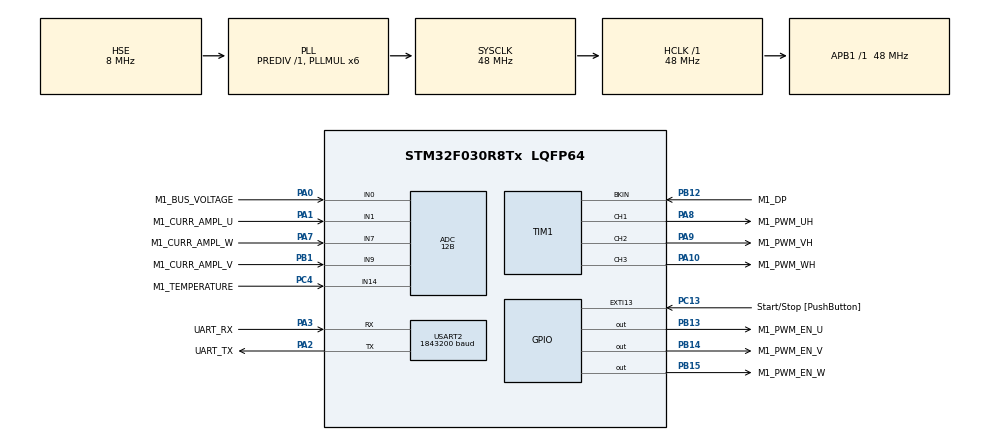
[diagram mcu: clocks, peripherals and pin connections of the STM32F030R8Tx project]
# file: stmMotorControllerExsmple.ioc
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ADC.ClockPrescaler=ADC_CLOCK_ASYNC_DIV1
ADC.ContinuousConvMode=DISABLE
ADC.DMAContinuousRequests=ENABLE
ADC.DataAlign=ADC_DATAALIGN_LEFT
ADC.DiscontinuousConvMode=DISABLE
ADC.EOCSelection=ADC_EOC_SINGLE_CONV
ADC.EnableAnalogWatchDog=false
ADC.ExternalTrigConv=ADC_EXTERNALTRIGCONV_T1_TRGO
ADC.ExternalTrigConvEdge=ADC_EXTERNALTRIGCONVEDGE_RISING
ADC.LowPowerAutoPowerOff=DISABLE
ADC.LowPowerAutoWait=DISABLE
ADC.Overrun=ADC_OVR_DATA_PRESERVED
ADC.Resolution=ADC_RESOLUTION_12B
ADC.SamplingTime=ADC_SAMPLETIME_7CYCLES_5
ADC.ScanConvMode=ADC_SCAN_DIRECTION_FORWARD
Dma.ADC.0.Direction=DMA_PERIPH_TO_MEMORY
Dma.ADC.0.Instance=DMA1_Channel1
Dma.ADC.0.MemDataAlignment=DMA_MDATAALIGN_HALFWORD
Dma.ADC.0.MemInc=DMA_MINC_ENABLE
Dma.ADC.0.Mode=DMA_CIRCULAR
Dma.ADC.0.PeriphDataAlignment=DMA_PDATAALIGN_HALFWORD
Dma.ADC.0.PeriphInc=DMA_PINC_DISABLE
Dma.ADC.0.Priority=DMA_PRIORITY_HIGH
Dma.Request0=ADC
Dma.Request1=USART2_RX
Dma.Request2=USART2_TX
Dma.USART2_RX.1.Direction=DMA_PERIPH_TO_MEMORY
Dma.USART2_RX.1.Instance=DMA1_Channel5
Dma.USART2_RX.1.MemDataAlignment=DMA_MDATAALIGN_BYTE
Dma.USART2_RX.1.MemInc=DMA_MINC_ENABLE
Dma.USART2_RX.1.Mode=DMA_NORMAL
Dma.USART2_RX.1.PeriphDataAlignment=DMA_PDATAALIGN_BYTE
Dma.USART2_RX.1.PeriphInc=DMA_PINC_DISABLE
Dma.USART2_RX.1.Priority=DMA_PRIORITY_LOW
Dma.USART2_TX.2.Direction=DMA_MEMORY_TO_PERIPH
Dma.USART2_TX.2.Instance=DMA1_Channel4
Dma.USART2_TX.2.MemDataAlignment=DMA_MDATAALIGN_BYTE
Dma.USART2_TX.2.MemInc=DMA_MINC_ENABLE
Dma.USART2_TX.2.Mode=DMA_NORMAL
Dma.USART2_TX.2.PeriphDataAlignment=DMA_PDATAALIGN_BYTE
Dma.USART2_TX.2.PeriphInc=DMA_PINC_DISABLE
Dma.USART2_TX.2.Priority=DMA_PRIORITY_LOW
ExtraMW=MotorControl
ExtraMW.MotorControl.Config=MotorControl
ExtraMW.MotorControl.Mode=MotorControl
ExtraMW.MotorControl.Root=MCSDK_v6.3.0-Full/MotorControl
ExtraMW.MotorControl.Template=templates
Mcu.Family=STM32F0
Mcu.Name=STM32F030R8Tx
Mcu.Package=LQFP64
MotorControl.ADC_AHBPERIPH=RCC_AHBPeriph_ADC
MotorControl.ADC_CLOCK_WB_DIV=1
MotorControl.ADC_PERIPH=ADC1
MotorControl.ADC_REFERENCE_VOLTAGE=3.3
MotorControl.BOARD=NUCLEO-F030R8
MotorControl.BUS_VOLTAGE_READING=true
MotorControl.CCMRAM_ENABLED=false
MotorControl.CLOCK_FREQUENCY=CPU_CLK_48_MHZ
MotorControl.CLOCK_SOURCE=EXTERNAL
MotorControl.CPU_CLK_48_MHZ=true
MotorControl.CTLBOARD_NAME=NUCLEO-F030R8
MotorControl.CUBE_MX_VER=6.11.1
MotorControl.CURRENT_READING_TOPOLOGY=THREE_SHUNT
MotorControl.CURR_SAMPLING_TIME=7
MotorControl.DBG_MCU_LOAD_MEASURE=false
MotorControl.DEBUG_DAC_FUNCTIONALITY_EN=false
MotorControl.DP_EMERGENCY_STOP_GPIO_PIN=LL_GPIO_PIN_12
MotorControl.DP_EMERGENCY_STOP_GPIO_PORT=GPIOB
MotorControl.DRIVES_NUMBER_SELECTION=SINGLEDRIVE
MotorControl.DRIVE_NUMBER=1
MotorControl.DRIVE_TYPE=FOC
MotorControl.ENCODER_AVAILABLE=false
MotorControl.ENCODER_PPR=400
MotorControl.EXT_CLK_8_MHZ=true
MotorControl.EXT_CLOCK_FREQUENCY=EXT_CLK_8_MHZ
MotorControl.FEEDBACK_NET_FILTERING=false
MotorControl.HALL_SENSORS_AVAILABLE=false
MotorControl.HIGH_SIDE_IDLE_STATE=false
MotorControl.HWV_CS=ThreeShunt_AmplifiedCurrents
MotorControl.HWV_DP=SingleErrorTrigger_FixedReference
MotorControl.HWV_PWM=DrivingHighSidesAndThreeEnables
MotorControl.HW_COMPLEMENTED_LOW_SIDE=true
MotorControl.HW_DEAD_TIME_NS=550
MotorControl.IPs=NVIC,RCC,SYS,MotorControl,TIM1,ADC,USART2,DMA
MotorControl.LOW_MEMORY_FOOTPRINT_REG=false
MotorControl.LOW_SIDE_IDLE_STATE=false
MotorControl.LOW_SIDE_SIGNALS_ENABLING=ES_GPIO
MotorControl.M1_AMPLIFICATION_GAIN=1.53
MotorControl.M1_ANGC={0,0,0,0,0,0,0,0}
MotorControl.M1_AUXILIARY_SPEED_SENSOR=NONE
MotorControl.M1_BEMF_CONSISTENCY_GAIN=64
MotorControl.M1_BEMF_CONSISTENCY_TOL=64
MotorControl.M1_BOARD_MAX_CURRENT=1.2
MotorControl.M1_BUS_VOLTAGE_READING=true
MotorControl.M1_COMMUTATION_STEP_TIME_BUF_SIZE=12
MotorControl.M1_CONSTANT1_D=3445
MotorControl.M1_CONSTANT1_Q=3445
MotorControl.M1_CONSTANT2_QD=3257
MotorControl.M1_CS_ADC_NUM=1
MotorControl.M1_CS_ADC_PHASE_SHARED=NONE
MotorControl.M1_CS_ADC_U=ADC1
MotorControl.M1_CS_ADC_V=ADC1
MotorControl.M1_CS_ADC_W=ADC1
MotorControl.M1_CS_CHANNEL_U=1
MotorControl.M1_CS_CHANNEL_V=9
MotorControl.M1_CS_CHANNEL_W=7
MotorControl.M1_CURRENT_AMPLIFICATION_TOPO=EXTERNAL
MotorControl.M1_CURRENT_SENSING_TOPO=THREE_SHUNT
MotorControl.M1_CURR_SAMPLING_TIME=7
MotorControl.M1_DBG_OPEN_LOOP_ENABLE=false
MotorControl.M1_DC_CURRENT_RS_MEAS=1.2
MotorControl.M1_DEFAULT_CONTROL_MODE=STC_SPEED_MODE
MotorControl.M1_DEFAULT_FLUX_COMPONENT=0
MotorControl.M1_DEFAULT_TARGET_SPEED_RPM=3000
MotorControl.M1_DEFAULT_TORQUE_COMPONENT=0
MotorControl.M1_DISCONTINUOUS_PWM=false
MotorControl.M1_DP_BKIN_FILTER=3
MotorControl.M1_DP_BKIN_MODE=EXT_MODE
MotorControl.M1_DP_BKIN_POLARITY=EMSTOP_ACTIVE_LOW
MotorControl.M1_DP_DESTINATION=TIM_BKIN
MotorControl.M1_DP_TOPOLOGY=EXTERNAL
MotorControl.M1_DRIVE_TYPE=FOC
MotorControl.M1_ENABLE_SL_ALGO_FROM_PHASE=2
MotorControl.M1_ENCODER_PPR=400
MotorControl.M1_F1=1024
MotorControl.M1_F2=16384
MotorControl.M1_FEED_FORWARD_CURRENT_REG_ENABLING=false
MotorControl.M1_FLUX_WEAKENING_ENABLING=false
MotorControl.M1_FW_KIDIV=32768
MotorControl.M1_FW_KI_GAIN=5000
MotorControl.M1_FW_KPDIV=32768
MotorControl.M1_FW_KP_GAIN=3000
MotorControl.M1_FW_VOLTAGE_REF=985
MotorControl.M1_GAIN1=-1380
MotorControl.M1_GAIN2=2898
MotorControl.M1_HALL_PHASE_SHIFT=300
MotorControl.M1_HALL_SENSORS_PLACEMENT=DEGREES_120
MotorControl.M1_HIGH_SIDE_IDLE_STATE=false
MotorControl.M1_HW_DEAD_TIME_NS=550
MotorControl.M1_ICL_ENABLED=false
MotorControl.M1_ID_DEMAG=-1.2
MotorControl.M1_IQMAX=1.2
MotorControl.M1_LDLQ_RATIO=1.000
MotorControl.M1_LOW_SIDE_IDLE_STATE=false
MotorControl.M1_LOW_SIDE_SIGNALS_ENABLING=ES_GPIO
MotorControl.M1_LS=0.000018
MotorControl.M1_MAX_APPLICATION_SPEED=15000
MotorControl.M1_MAX_MODULATION_INDEX=97
MotorControl.M1_MIN_APPLICATION_SPEED=0
MotorControl.M1_MOTOR_MAX_SPEED_RPM=15000
MotorControl.M1_MOTOR_NAME=Bull Running BR2804-1700
MotorControl.M1_MOTOR_RATED_FLUX=0.002799417
MotorControl.M1_MOTOR_VOLTAGE_CONSTANT=0.4
MotorControl.M1_MTPA_ENABLING=false
MotorControl.M1_NB_CONSECUTIVE_TESTS=2
MotorControl.M1_NOMINAL_BUS_VOLTAGE_V=12
MotorControl.M1_NOMINAL_CURRENT=1.2
MotorControl.M1_OBS_MINIMUM_SPEED_RPM=3000
MotorControl.M1_OCP_TOPOLOGY=NONE
MotorControl.M1_OFST={0,0,0,0,0,0,0,0}
MotorControl.M1_ON_OVER_VOLTAGE=TURN_OFF_PWM
MotorControl.M1_OVERMODULATION=false
MotorControl.M1_OVP_THRESHOLD_HIGH=14
MotorControl.M1_OV_TEMPERATURE_HYSTERESIS_C=10
MotorControl.M1_OV_TEMPERATURE_PROT_ENABLING=true
MotorControl.M1_OV_TEMPERATURE_THRESHOLD_C=110
MotorControl.M1_OV_VOLTAGE_PROT_ENABLING=true
MotorControl.M1_OV_VOLTAGE_THRESHOLD_V=14
MotorControl.M1_PHASE1_DURATION=1000
MotorControl.M1_PHASE1_FINAL_CURRENT=1.2
MotorControl.M1_PHASE1_FINAL_SPEED_RPM=0
MotorControl.M1_PHASE2_DURATION=3333
MotorControl.M1_PHASE2_FINAL_CURRENT=1.2
MotorControl.M1_PHASE2_FINAL_SPEED_RPM=3333
MotorControl.M1_PHASE3_DURATION=0
MotorControl.M1_PHASE3_FINAL_CURRENT=1.2
MotorControl.M1_PHASE3_FINAL_SPEED_RPM=3333
MotorControl.M1_PHASE4_DURATION=0
MotorControl.M1_PHASE4_FINAL_CURRENT=1.2
MotorControl.M1_PHASE4_FINAL_SPEED_RPM=3333
MotorControl.M1_PHASE5_DURATION=0
MotorControl.M1_PHASE5_FINAL_CURRENT=1.2
MotorControl.M1_PHASE5_FINAL_SPEED_RPM=3333
MotorControl.M1_PID_FLUX_KD_DEFAULT=100
MotorControl.M1_PID_FLUX_KI_DEFAULT=197
MotorControl.M1_PID_FLUX_KP_DEFAULT=965
MotorControl.M1_PID_SPEED_KD_DEFAULT=0
MotorControl.M1_PID_SPEED_KI_DEFAULT=1271
MotorControl.M1_PID_SPEED_KP_DEFAULT=3952
MotorControl.M1_PID_TORQUE_KD_DEFAULT=100
MotorControl.M1_PID_TORQUE_KI_DEFAULT=197
MotorControl.M1_PID_TORQUE_KP_DEFAULT=965
MotorControl.M1_PLL_KI_GAIN=44
MotorControl.M1_PLL_KP_GAIN=1862
MotorControl.M1_POLE_PAIR_NUM=7
MotorControl.M1_POSITION_CTRL_ENABLING=false
MotorControl.M1_POTENTIOMETER_ENABLE=false
MotorControl.M1_POWERBOARD_NAME=X-NUCLEO-IHM16M1
MotorControl.M1_PWM_CHARGE_BOOT_CAP_DUTY_CYCLES=0.000
MotorControl.M1_PWM_CHARGE_BOOT_CAP_MS=10
MotorControl.M1_PWM_DRIVER_PN=Driver or IGBT or MOSFET Part Number
MotorControl.M1_PWM_FREQUENCY=30000
MotorControl.M1_PWM_TIMER_BRK_IRQ=TIM1_BRK_UP_TRG_COM
MotorControl.M1_PWM_TIMER_SELECTION=PWM_TIM1
MotorControl.M1_PWM_TIMER_UP_IRQ=TIM1_BRK_UP_TRG_COM
MotorControl.M1_REGULATION_EXECUTION_RATE=1
MotorControl.M1_RS=0.11
MotorControl.M1_RSHUNT=0.33
MotorControl.M1_SEGDIV=0
MotorControl.M1_SHARED_SIGNAL_ENABLE=false
MotorControl.M1_SPD_DIFFERENTIAL_TERM_ENABLING=false
MotorControl.M1_SPEED_BAND_LOWER_LIMIT=15
MotorControl.M1_SPEED_BAND_UPPER_LIMIT=17
MotorControl.M1_SPEED_FEEDBACK_CHECK=true
MotorControl.M1_SPEED_LOOP_FREQUENCY_HZ=1000
MotorControl.M1_SPEED_SENSOR=STO_PLL
MotorControl.M1_SP_KDDIV=16
MotorControl.M1_SP_KIDIV=16384
MotorControl.M1_SP_KPDIV=64
MotorControl.M1_SS_MEAS_ERRORS_BEFORE_FAULTS=3
MotorControl.M1_STARTING_ANGLE_DEG=0
MotorControl.M1_STO_FIFO_DEPTH_01HZ=64
MotorControl.M1_STO_FIFO_DEPTH_DPP=64
MotorControl.M1_SW_DEADTIME_NS=525
MotorControl.M1_T0_C=25
MotorControl.M1_TEMPERATURE_READING=true
MotorControl.M1_TEMP_ADC_SAMPLING_TIME=28
MotorControl.M1_TEMP_FDBK_ADC=ADC1
MotorControl.M1_TEMP_FDBK_CHANNEL=ADC_CHANNEL_14
MotorControl.M1_TF_KDDIV=8192
MotorControl.M1_TF_KIDIV=16384
MotorControl.M1_TF_KPDIV=16384
MotorControl.M1_TNOISE_NS=500
MotorControl.M1_TRANSITION_DURATION=25
MotorControl.M1_TRISE_NS=500
MotorControl.M1_T_MAX=110
MotorControl.M1_UD_VOLTAGE_THRESHOLD_V=7
MotorControl.M1_USE_INTERNAL_OPAMP=false
MotorControl.M1_UV_VOLTAGE_PROT_ENABLING=true
MotorControl.M1_V0_V=0.579
MotorControl.M1_VARIANCE_THRESHOLD=0.25
MotorControl.M1_VBUS_ADC=ADC1
MotorControl.M1_VBUS_ADC_SAMPLING_TIME=28
MotorControl.M1_VBUS_CHANNEL=ADC_CHANNEL_0
MotorControl.M1_VBUS_PARTITIONING_FACTOR=0.0625
MotorControl.M1_dV_dT=0.027
MotorControl.MAX_READABLE_CURRENT=3.272
MotorControl.MCPA_OVER_UART_A_STREAM=10
MotorControl.MCP_ASPEP_OVER_UART=true
MotorControl.MCP_ASYNC_EN=true
MotorControl.MCP_ASYNC_OVER_ASPEP_EN=true
MotorControl.MCP_ASYNC_OVER_UART_A_EN=true
MotorControl.MCP_DMACH_RX_UART_A=5
MotorControl.MCP_DMACH_TX_UART_A=4
MotorControl.MCP_DMA_RX_UART_A=DMA1
MotorControl.MCP_DMA_TX_UART_A=DMA1
MotorControl.MCP_EN=true
MotorControl.MCP_IRQ_HANDLER_DMA_RX_UART_A=DMA1_Channel4_5_IRQHandler
MotorControl.MCP_IRQ_HANDLER_UART_A=USART2_IRQHandler
MotorControl.MCP_OVER_ASPEP_EN=true
MotorControl.MCP_OVER_STLNK_EN=false
MotorControl.MCP_OVER_UART_A_EN=true
MotorControl.MCP_OVER_UART_B_EN=false
MotorControl.MCP_RX_SYNC_PAYLOAD_MAX=128
MotorControl.MCP_TX_ASYNC_PAYLOAD_MAX_UART_A=1024
MotorControl.MCP_TX_SYNC_PAYLOAD_MAX=128
MotorControl.MCU=STM32F030R8
MotorControl.MCU_FAMILY=STM32F0
MotorControl.MCU_LINE=STM32F0x0 Value Line
MotorControl.MCU_NAME=STM32F030R8Tx
MotorControl.MCU_PACKAGE=LQFP64
MotorControl.MCU_TYPE=STM32F030R8
MotorControl.MCU_USERNAME=STM32F030R8Tx
MotorControl.MC_WORKBENCH_VERSION=6.3.0
MotorControl.MOTOR_PROFILER=false
MotorControl.MOTOR_TYPE=PMSM
MotorControl.ON_OVER_VOLTAGE=TURN_OFF_PWM
MotorControl.OV_TEMPERATURE_PROT_ENABLING=true
MotorControl.OV_VOLTAGE_PROT_ENABLING=true
MotorControl.PHASE_UH_GPIO_PIN=LL_GPIO_PIN_8
MotorControl.PHASE_UH_GPIO_PORT=GPIOA
MotorControl.PHASE_UH_POLARITY=H_ACTIVE_HIGH
MotorControl.PHASE_UL_GPIO_PIN=LL_GPIO_PIN_13
MotorControl.PHASE_UL_GPIO_PORT=GPIOB
MotorControl.PHASE_UL_POLARITY=L_ACTIVE_HIGH
MotorControl.PHASE_U_CURR_ADC=ADC1
MotorControl.PHASE_U_CURR_CHANNEL=ADC_CHANNEL_1
MotorControl.PHASE_U_GPIO_PIN=LL_GPIO_PIN_1
MotorControl.PHASE_U_GPIO_PORT=GPIOA
MotorControl.PHASE_VH_GPIO_PIN=LL_GPIO_PIN_9
MotorControl.PHASE_VH_GPIO_PORT=GPIOA
MotorControl.PHASE_VH_POLARITY=H_ACTIVE_HIGH
MotorControl.PHASE_VL_GPIO_PIN=LL_GPIO_PIN_14
MotorControl.PHASE_VL_GPIO_PORT=GPIOB
MotorControl.PHASE_VL_POLARITY=L_ACTIVE_HIGH
MotorControl.PHASE_V_CURR_ADC=ADC1
MotorControl.PHASE_V_CURR_CHANNEL=ADC_CHANNEL_9
MotorControl.PHASE_V_GPIO_PIN=LL_GPIO_PIN_1
MotorControl.PHASE_V_GPIO_PORT=GPIOB
MotorControl.PHASE_WH_GPIO_PIN=LL_GPIO_PIN_10
MotorControl.PHASE_WH_GPIO_PORT=GPIOA
MotorControl.PHASE_WH_POLARITY=H_ACTIVE_HIGH
MotorControl.PHASE_WL_GPIO_PIN=LL_GPIO_PIN_15
MotorControl.PHASE_WL_GPIO_PORT=GPIOB
MotorControl.PHASE_WL_POLARITY=L_ACTIVE_HIGH
MotorControl.PHASE_W_CURR_ADC=ADC1
MotorControl.PHASE_W_CURR_CHANNEL=ADC_CHANNEL_7
MotorControl.PHASE_W_GPIO_PIN=LL_GPIO_PIN_7
MotorControl.PHASE_W_GPIO_PORT=GPIOA
MotorControl.POTENTIOMETER_READING=false
MotorControl.PWM_FREQUENCY=30000
MotorControl.PWM_TIMER_SELECTION=PWM_TIM1
MotorControl.REGULATION_EXECUTION_RATE=1
MotorControl.RTOS=NONE
MotorControl.R_BRAKE_SWITCH_OFF_THRES_V=12
MotorControl.SINGLEDRIVE=true
MotorControl.SPD_DIFFERENTIAL_TERM_ENABLING=false
MotorControl.SPEED_SENSOR_SELECTION=STATE_OBSERVER_PLL
MotorControl.START_STOP_BTN=true
MotorControl.START_STOP_GPIO_PIN=LL_GPIO_PIN_13
MotorControl.START_STOP_GPIO_PORT=GPIOC
MotorControl.START_STOP_POLARITY=DIN_ACTIVE_LOW
MotorControl.START_STOP_POLARITY_EDGE=GPIO_NOPULL
MotorControl.STATE_OBSERVER_PLL=true
MotorControl.STM32F030R8=true
MotorControl.SW_DEADTIME_NS=525
MotorControl.TEMPERATURE_READING=true
MotorControl.TEMP_ADC_SAMPLING_TIME=28
MotorControl.TEMP_FDBK_ADC=ADC1
MotorControl.TEMP_FDBK_CHANNEL=ADC_CHANNEL_14
MotorControl.TEMP_FDBK_GPIO_PIN=LL_GPIO_PIN_4
MotorControl.TEMP_FDBK_GPIO_PORT=GPIOC
MotorControl.TFDIFFERENTIAL_TERM_ENABLING=false
MotorControl.THREE_SHUNT=true
MotorControl.TRISE_NS=500
MotorControl.USART_RX_GPIO_PIN=LL_GPIO_PIN_3
MotorControl.USART_RX_GPIO_PORT=GPIOA
MotorControl.USART_SELECTION=USE_USART2
MotorControl.USART_SELECTION_A=USART2
MotorControl.USART_SPEED=1843200
MotorControl.USART_TX_GPIO_PIN=LL_GPIO_PIN_2
MotorControl.USART_TX_GPIO_PORT=GPIOA
MotorControl.USE_3OPAMPS=false
MotorControl.USE_INTERNAL_OPAMP=false
MotorControl.UV_VOLTAGE_PROT_ENABLING=true
MotorControl.VBUS_ADC=ADC1
MotorControl.VBUS_ADC_SAMPLING_TIME=28
MotorControl.VBUS_CHANNEL=ADC_CHANNEL_0
MotorControl.VBUS_GPIO_PIN=LL_GPIO_PIN_0
MotorControl.VBUS_GPIO_PORT=GPIOA
MotorControl.WB_UI_CUTOFF_FREQUENCY=6000
MotorControl.WB_UI_DP_DISABLING_ENABLE=false
MotorControl.WB_UI_ENCODER_HAS_INDEX_PIN=false
MotorControl.WB_UI_FLUX_TARGET=0
MotorControl.WB_UI_FRICTION=0.437
MotorControl.WB_UI_INERTIA=0.348
MotorControl.WB_UI_MAGNETIC_STRUCTURE=SM-PMSM
MotorControl.WB_UI_MAX_CURRENT=1.2
MotorControl.WB_UI_MAX_NOMINAL_DC_VOLTAGE=12
MotorControl.WB_UI_MAX_PWMFREQUENCY=100000
MotorControl.WB_UI_MOTOR_DESCRIPTION=External rotor type - 7 poles pairs brushless - DC motor
MotorControl.WB_UI_PW_BOARD_MAX_RATED_CURRENT=2.12
MotorControl.WB_UI_PW_BOARD_MAX_VOLTAGE=45
MotorControl.WB_UI_PW_BOARD_MIN_VOLTAGE=7
MotorControl.WB_UI_VPOL=1.559
MotorControl.WB_to_Mx_template_version=24-04-17
MotorControl.WB_to_Mx_version=6.2.3
NVIC.DMA1_Channel1_IRQn=true\:1\:0\:true\:true\:false\:2\:true\:true\:true
NVIC.DMA1_Channel4_5_IRQn=true\:3\:0\:true\:true\:false\:3\:true\:true\:true
NVIC.EXTI4_15_IRQn=true\:3\:0\:false\:true\:false\:5\:true\:true\:true
NVIC.TIM1_BRK_UP_TRG_COM_IRQn=true\:0\:0\:false\:true\:false\:4\:true\:true\:true
NVIC.USART2_IRQn=true\:3\:0\:true\:true\:false\:1\:true\:true\:true
PA0.GPIO_Label=M1_BUS_VOLTAGE
PA0.Mode=IN0
PA0.Signal=ADC_IN0
PA1.GPIO_Label=M1_CURR_AMPL_U
PA1.Mode=IN1
PA1.Signal=ADC_IN1
PA10.GPIO_Label=M1_PWM_WH
PA10.GPIO_PuPd=GPIO_PULLDOWN
PA10.GPIO_Speed=GPIO_SPEED_FREQ_HIGH
PA10.Signal=S_TIM1_CH3
PA13.GPIO_Label=TMS
PA13.Mode=Serial_Wire
PA13.Signal=SYS_SWDIO
PA14.GPIO_Label=TCK
PA14.Mode=Serial_Wire
PA14.Signal=SYS_SWCLK
PA2.GPIO_Label=UART_TX
PA2.GPIO_Mode=GPIO_MODE_AF_PP
PA2.GPIO_PuPd=GPIO_NOPULL
PA2.GPIO_Speed=GPIO_SPEED_FREQ_LOW
PA2.Mode=Asynchronous
PA2.Signal=USART2_TX
PA3.GPIO_Label=UART_RX
PA3.GPIO_Mode=GPIO_MODE_AF_PP
PA3.GPIO_PuPd=GPIO_NOPULL
PA3.GPIO_Speed=GPIO_SPEED_FREQ_LOW
PA3.Mode=Asynchronous
PA3.Signal=USART2_RX
PA7.GPIO_Label=M1_CURR_AMPL_W
PA7.Mode=IN7
PA7.Signal=ADC_IN7
PA8.GPIO_Label=M1_PWM_UH
PA8.GPIO_PuPd=GPIO_PULLDOWN
PA8.GPIO_Speed=GPIO_SPEED_FREQ_HIGH
PA8.Signal=S_TIM1_CH1
PA9.GPIO_Label=M1_PWM_VH
PA9.GPIO_PuPd=GPIO_PULLDOWN
PA9.GPIO_Speed=GPIO_SPEED_FREQ_HIGH
PA9.Signal=S_TIM1_CH2
PB1.GPIO_Label=M1_CURR_AMPL_V
PB1.Mode=IN9
PB1.Signal=ADC_IN9
PB12.GPIO_Label=M1_DP
PB12.GPIO_PuPd=GPIO_PULLUP
PB12.Mode=Activate-Break-Input
PB12.Signal=TIM1_BKIN
PB13.GPIO_Label=M1_PWM_EN_U
PB13.GPIO_PuPd=GPIO_PULLDOWN
PB13.GPIO_Speed=GPIO_SPEED_FREQ_HIGH
PB13.Signal=GPIO_Output
PB14.GPIO_Label=M1_PWM_EN_V
PB14.GPIO_PuPd=GPIO_PULLDOWN
PB14.GPIO_Speed=GPIO_SPEED_FREQ_HIGH
PB14.Signal=GPIO_Output
PB15.GPIO_Label=M1_PWM_EN_W
PB15.GPIO_PuPd=GPIO_PULLDOWN
PB15.GPIO_Speed=GPIO_SPEED_FREQ_HIGH
PB15.Signal=GPIO_Output
PC13.GPIO_Label=Start/Stop [PushButton]
PC13.GPIO_ModeDefaultEXTI=GPIO_MODE_IT_FALLING
PC13.GPIO_PuPd=GPIO_NOPULL
PC13.Signal=GPXTI13
PC4.GPIO_Label=M1_TEMPERATURE
PC4.Mode=IN14
PC4.Signal=ADC_IN14
PF0-OSC_IN.Mode=HSE-External-Oscillator
PF0-OSC_IN.Signal=RCC_OSC_IN
PF1-OSC_OUT.Mode=HSE-External-Oscillator
PF1-OSC_OUT.Signal=RCC_OSC_OUT
ProjectManager.HeapSize=0x80
ProjectManager.StackSize=0x400
ProjectManager.TargetToolchain=STM32CubeIDE
RCC.AHBFreq_Value=48000000
RCC.APB1Freq_Value=48000000
RCC.APB1TimFreq_Value=48000000
RCC.EnbaleCSS=true
RCC.HCLKFreq_Value=48000000
RCC.HSE_VALUE=8000000
RCC.PLLMUL=RCC_PLL_MUL6
RCC.PLLSourceVirtual=RCC_PLLSOURCE_HSE
RCC.PREFETCH_ENABLE=1
RCC.SYSCLKFreq_VALUE=48000000
RCC.SYSCLKSource=RCC_SYSCLKSOURCE_PLLCLK
SH.S_TIM1_CH1.0=TIM1_CH1,PWM Generation1 CH1
SH.S_TIM1_CH2.0=TIM1_CH2,PWM Generation2 CH2
SH.S_TIM1_CH3.0=TIM1_CH3,PWM Generation3 CH3
TIM1.AutoReloadPreload=TIM_AUTORELOAD_PRELOAD_DISABLE
TIM1.AutomaticOutput=TIM_AUTOMATICOUTPUT_DISABLE
TIM1.BreakPolarity=TIM_BREAKPOLARITY_LOW
TIM1.BreakState=TIM_BREAK_ENABLE
TIM1.Channel-PWM\ Generation1\ CH1=TIM_CHANNEL_1
TIM1.Channel-PWM\ Generation2\ CH2=TIM_CHANNEL_2
TIM1.Channel-PWM\ Generation3\ CH3=TIM_CHANNEL_3
TIM1.Channel-PWM\ Generation4\ No\ Output=TIM_CHANNEL_4
TIM1.ClockDivision=TIM_CLOCKDIVISION_DIV2
TIM1.CounterMode=TIM_COUNTERMODE_CENTERALIGNED1
TIM1.LockLevel=TIM_LOCKLEVEL_OFF
TIM1.OC1Preload_PWM=ENABLE
TIM1.OC2Preload_PWM=ENABLE
TIM1.OC3Preload_PWM=ENABLE
TIM1.OC4Preload_PWM=ENABLE
TIM1.OCIdleState_1=TIM_OCIDLESTATE_RESET
TIM1.OCIdleState_2=TIM_OCIDLESTATE_RESET
TIM1.OCIdleState_3=TIM_OCIDLESTATE_RESET
TIM1.OCIdleState_4=TIM_OCIDLESTATE_RESET
TIM1.OCMode_PWM-PWM\ Generation1\ CH1=TIM_OCMODE_PWM1
TIM1.OCMode_PWM-PWM\ Generation2\ CH2=TIM_OCMODE_PWM1
TIM1.OCMode_PWM-PWM\ Generation3\ CH3=TIM_OCMODE_PWM1
TIM1.OCMode_PWM-PWM\ Generation4\ No\ Output=TIM_OCMODE_PWM2
TIM1.OCPolarity_1=TIM_OCPOLARITY_HIGH
TIM1.OCPolarity_2=TIM_OCPOLARITY_HIGH
TIM1.OCPolarity_3=TIM_OCPOLARITY_HIGH
TIM1.OCPolarity_4=TIM_OCPOLARITY_HIGH
TIM1.OffStateIDLEMode=TIM_OSSI_ENABLE
TIM1.OffStateRunMode=TIM_OSSR_ENABLE
TIM1.Period=((PWM_PERIOD_CYCLES) / 2)
TIM1.Prescaler=((TIM_CLOCK_DIVIDER) - 1)
TIM1.Pulse-PWM\ Generation1\ CH1=((PWM_PERIOD_CYCLES) / 4)
TIM1.Pulse-PWM\ Generation2\ CH2=((PWM_PERIOD_CYCLES) / 4)
TIM1.Pulse-PWM\ Generation3\ CH3=((PWM_PERIOD_CYCLES) / 4)
TIM1.Pulse-PWM\ Generation4\ No\ Output=(((PWM_PERIOD_CYCLES) / 2) - (HTMIN))
TIM1.RepetitionCounter=(REP_COUNTER)
TIM1.TIM_MasterOutputTrigger=TIM_TRGO_OC4REF
TIM1.TIM_MasterSlaveMode=TIM_MASTERSLAVEMODE_DISABLE
USART2.BaudRate=1843200
USART2.VirtualMode-Asynchronous=VM_ASYNC
USART2.WordLength=WORDLENGTH_8B
VP_MotorControl_MC_ENABLED.Mode=Enabled
VP_TIM1_VS_no_output4.Mode=PWM Generation4 No Output
board=custom

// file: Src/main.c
/* USER CODE BEGIN Header */
/**
  ******************************************************************************
  * @file           : main.c
  * @brief          : Main program body
  ******************************************************************************
  * @attention
  *
  * Copyright (c) 2024 STMicroelectronics.
  * All rights reserved.
  *
  * This software is licensed under terms that can be found in the LICENSE file
  * in the root directory of this software component.
  * If no LICENSE file comes with this software, it is provided AS-IS.
  *
  ******************************************************************************
  */
/* USER CODE END Header */
#include "main.h"

ADC_HandleTypeDef hadc;
DMA_HandleTypeDef hdma_adc;

TIM_HandleTypeDef htim1;

UART_HandleTypeDef huart2;
DMA_HandleTypeDef hdma_usart2_rx;
DMA_HandleTypeDef hdma_usart2_tx;

void SystemClock_Config(void);
static void MX_GPIO_Init(void);
static void MX_DMA_Init(void);
static void MX_ADC_Init(void);
static void MX_TIM1_Init(void);
static void MX_USART2_UART_Init(void);
static void MX_NVIC_Init(void);

int main(void)
{

  /* USER CODE BEGIN 1 */
//NOTE: this code is not tested, nor anywhere useful, just a stud that makes
//every code generated from sdk. which seems to be for larger applications
  /* USER CODE END 1 */

  /* MCU Configuration--------------------------------------------------------*/

  /* Reset of all peripherals, Initializes the Flash interface and the Systick. */
  HAL_Init();

  /* Configure the system clock */
  SystemClock_Config();

  /* Initialize all configured peripherals */
  MX_GPIO_Init();
  MX_DMA_Init();
  MX_ADC_Init();
  MX_TIM1_Init();
  MX_USART2_UART_Init();
  MX_MotorControl_Init();

  /* Initialize interrupts */
  MX_NVIC_Init();

  /* Infinite loop */
  while (1)
  {

  }
}

void SystemClock_Config(void)
{
  RCC_OscInitTypeDef RCC_OscInitStruct = {0};
  RCC_ClkInitTypeDef RCC_ClkInitStruct = {0};

  /** Initializes the RCC Oscillators according to the specified parameters
  * in the RCC_OscInitTypeDef structure.
  */
  RCC_OscInitStruct.OscillatorType = RCC_OSCILLATORTYPE_HSI14|RCC_OSCILLATORTYPE_HSE;
  RCC_OscInitStruct.HSEState = RCC_HSE_ON;
  RCC_OscInitStruct.HSI14State = RCC_HSI14_ON;
  RCC_OscInitStruct.HSI14CalibrationValue = 16;
  RCC_OscInitStruct.PLL.PLLState = RCC_PLL_ON;
  RCC_OscInitStruct.PLL.PLLSource = RCC_PLLSOURCE_HSE;
  RCC_OscInitStruct.PLL.PLLMUL = RCC_PLL_MUL6;
  RCC_OscInitStruct.PLL.PREDIV = RCC_PREDIV_DIV1;
  if (HAL_RCC_OscConfig(&RCC_OscInitStruct) != HAL_OK)
  {
    Error_Handler();
  }

  /** Initializes the CPU, AHB and APB buses clocks
  */
  RCC_ClkInitStruct.ClockType = RCC_CLOCKTYPE_HCLK|RCC_CLOCKTYPE_SYSCLK
                              |RCC_CLOCKTYPE_PCLK1;
  RCC_ClkInitStruct.SYSCLKSource = RCC_SYSCLKSOURCE_PLLCLK;
  RCC_ClkInitStruct.AHBCLKDivider = RCC_SYSCLK_DIV1;
  RCC_ClkInitStruct.APB1CLKDivider = RCC_HCLK_DIV1;

  if (HAL_RCC_ClockConfig(&RCC_ClkInitStruct, FLASH_LATENCY_1) != HAL_OK)
  {
    Error_Handler();
  }

  /** Enables the Clock Security System
  */
  HAL_RCC_EnableCSS();
}

/**
  * @brief NVIC Configuration.
  * @retval None
  */
static void MX_NVIC_Init(void)
{
  /* USART2_IRQn interrupt configuration */
  HAL_NVIC_SetPriority(USART2_IRQn, 3, 0);
  HAL_NVIC_EnableIRQ(USART2_IRQn);
  /* DMA1_Channel1_IRQn interrupt configuration */
  HAL_NVIC_SetPriority(DMA1_Channel1_IRQn, 1, 0);
  HAL_NVIC_EnableIRQ(DMA1_Channel1_IRQn);
  /* DMA1_Channel4_5_IRQn interrupt configuration */
  HAL_NVIC_SetPriority(DMA1_Channel4_5_IRQn, 3, 0);
  HAL_NVIC_EnableIRQ(DMA1_Channel4_5_IRQn);
  /* TIM1_BRK_UP_TRG_COM_IRQn interrupt configuration */
  HAL_NVIC_SetPriority(TIM1_BRK_UP_TRG_COM_IRQn, 0, 0);
  HAL_NVIC_EnableIRQ(TIM1_BRK_UP_TRG_COM_IRQn);
  /* EXTI4_15_IRQn interrupt configuration */
  HAL_NVIC_SetPriority(EXTI4_15_IRQn, 3, 0);
  HAL_NVIC_EnableIRQ(EXTI4_15_IRQn);
}

static void MX_ADC_Init(void)
{

  ADC_ChannelConfTypeDef sConfig = {0};

  /** Configure the global features of the ADC (Clock, Resolution, Data Alignment and number of conversion)
  */
  hadc.Instance = ADC1;
  hadc.Init.ClockPrescaler = ADC_CLOCK_ASYNC_DIV1;
  hadc.Init.Resolution = ADC_RESOLUTION_12B;
  hadc.Init.DataAlign = ADC_DATAALIGN_LEFT;
  hadc.Init.ScanConvMode = ADC_SCAN_DIRECTION_FORWARD;
  hadc.Init.EOCSelection = ADC_EOC_SINGLE_CONV;
  hadc.Init.LowPowerAutoWait = DISABLE;
  hadc.Init.LowPowerAutoPowerOff = DISABLE;
  hadc.Init.ContinuousConvMode = DISABLE;
  hadc.Init.DiscontinuousConvMode = DISABLE;
  hadc.Init.ExternalTrigConv = ADC_EXTERNALTRIGCONV_T1_TRGO;
  hadc.Init.ExternalTrigConvEdge = ADC_EXTERNALTRIGCONVEDGE_RISING;
  hadc.Init.DMAContinuousRequests = ENABLE;
  hadc.Init.Overrun = ADC_OVR_DATA_PRESERVED;
  if (HAL_ADC_Init(&hadc) != HAL_OK)
  {
    Error_Handler();
  }

  /** Configure for the selected ADC regular channel to be converted.
  */
  sConfig.Channel = ADC_CHANNEL_0;
  sConfig.Rank = ADC_RANK_CHANNEL_NUMBER;
  sConfig.SamplingTime = ADC_SAMPLETIME_7CYCLES_5;
  if (HAL_ADC_ConfigChannel(&hadc, &sConfig) != HAL_OK)
  {
    Error_Handler();
  }

  /** Configure for the selected ADC regular channel to be converted.
  */
  sConfig.Channel = ADC_CHANNEL_1;
  if (HAL_ADC_ConfigChannel(&hadc, &sConfig) != HAL_OK)
  {
    Error_Handler();
  }

  /** Configure for the selected ADC regular channel to be converted.
  */
  sConfig.Channel = ADC_CHANNEL_7;
  if (HAL_ADC_ConfigChannel(&hadc, &sConfig) != HAL_OK)
  {
    Error_Handler();
  }

  /** Configure for the selected ADC regular channel to be converted.
  */
  sConfig.Channel = ADC_CHANNEL_9;
  if (HAL_ADC_ConfigChannel(&hadc, &sConfig) != HAL_OK)
  {
    Error_Handler();
  }

  /** Configure for the selected ADC regular channel to be converted.
  */
  sConfig.Channel = ADC_CHANNEL_14;
  if (HAL_ADC_ConfigChannel(&hadc, &sConfig) != HAL_OK)
  {
    Error_Handler();
  }

}

static void MX_TIM1_Init(void)
{

  TIM_MasterConfigTypeDef sMasterConfig = {0};
  TIM_OC_InitTypeDef sConfigOC = {0};
  TIM_BreakDeadTimeConfigTypeDef sBreakDeadTimeConfig = {0};

  htim1.Instance = TIM1;
  htim1.Init.Prescaler = ((TIM_CLOCK_DIVIDER) - 1);
  htim1.Init.CounterMode = TIM_COUNTERMODE_CENTERALIGNED1;
  htim1.Init.Period = ((PWM_PERIOD_CYCLES) / 2);
  htim1.Init.ClockDivision = TIM_CLOCKDIVISION_DIV2;
  htim1.Init.RepetitionCounter = (REP_COUNTER);
  htim1.Init.AutoReloadPreload = TIM_AUTORELOAD_PRELOAD_DISABLE;
  if (HAL_TIM_PWM_Init(&htim1) != HAL_OK)
  {
    Error_Handler();
  }
  sMasterConfig.MasterOutputTrigger = TIM_TRGO_OC4REF;
  sMasterConfig.MasterSlaveMode = TIM_MASTERSLAVEMODE_DISABLE;
  if (HAL_TIMEx_MasterConfigSynchronization(&htim1, &sMasterConfig) != HAL_OK)
  {
    Error_Handler();
  }
  sConfigOC.OCMode = TIM_OCMODE_PWM1;
  sConfigOC.Pulse = ((PWM_PERIOD_CYCLES) / 4);
  sConfigOC.OCPolarity = TIM_OCPOLARITY_HIGH;
  sConfigOC.OCNPolarity = TIM_OCNPOLARITY_HIGH;
  sConfigOC.OCFastMode = TIM_OCFAST_DISABLE;
  sConfigOC.OCIdleState = TIM_OCIDLESTATE_RESET;
  sConfigOC.OCNIdleState = TIM_OCNIDLESTATE_RESET;
  if (HAL_TIM_PWM_ConfigChannel(&htim1, &sConfigOC, TIM_CHANNEL_1) != HAL_OK)
  {
    Error_Handler();
  }
  if (HAL_TIM_PWM_ConfigChannel(&htim1, &sConfigOC, TIM_CHANNEL_2) != HAL_OK)
  {
    Error_Handler();
  }
  if (HAL_TIM_PWM_ConfigChannel(&htim1, &sConfigOC, TIM_CHANNEL_3) != HAL_OK)
  {
    Error_Handler();
  }
  sConfigOC.OCMode = TIM_OCMODE_PWM2;
  sConfigOC.Pulse = (((PWM_PERIOD_CYCLES) / 2) - (HTMIN));
  if (HAL_TIM_PWM_ConfigChannel(&htim1, &sConfigOC, TIM_CHANNEL_4) != HAL_OK)
  {
    Error_Handler();
  }
  sBreakDeadTimeConfig.OffStateRunMode = TIM_OSSR_ENABLE;
  sBreakDeadTimeConfig.OffStateIDLEMode = TIM_OSSI_ENABLE;
  sBreakDeadTimeConfig.LockLevel = TIM_LOCKLEVEL_OFF;
  sBreakDeadTimeConfig.DeadTime = 0;
  sBreakDeadTimeConfig.BreakState = TIM_BREAK_ENABLE;
  sBreakDeadTimeConfig.BreakPolarity = TIM_BREAKPOLARITY_LOW;
  sBreakDeadTimeConfig.AutomaticOutput = TIM_AUTOMATICOUTPUT_DISABLE;
  if (HAL_TIMEx_ConfigBreakDeadTime(&htim1, &sBreakDeadTimeConfig) != HAL_OK)
  {
    Error_Handler();
  }
  HAL_TIM_MspPostInit(&htim1);

}

static void MX_USART2_UART_Init(void)
{

  huart2.Instance = USART2;
  huart2.Init.BaudRate = 1843200;
  huart2.Init.WordLength = UART_WORDLENGTH_8B;
  huart2.Init.StopBits = UART_STOPBITS_1;
  huart2.Init.Parity = UART_PARITY_NONE;
  huart2.Init.Mode = UART_MODE_TX_RX;
  huart2.Init.HwFlowCtl = UART_HWCONTROL_NONE;
  huart2.Init.OverSampling = UART_OVERSAMPLING_16;
  huart2.Init.OneBitSampling = UART_ONE_BIT_SAMPLE_DISABLE;
  huart2.AdvancedInit.AdvFeatureInit = UART_ADVFEATURE_NO_INIT;
  if (HAL_UART_Init(&huart2) != HAL_OK)
  {
    Error_Handler();
  }

}

static void MX_DMA_Init(void)
{

  /* DMA controller clock enable */
  __HAL_RCC_DMA1_CLK_ENABLE();

}

static void MX_GPIO_Init(void)
{
  GPIO_InitTypeDef GPIO_InitStruct = {0};

  /* GPIO Ports Clock Enable */
  __HAL_RCC_GPIOC_CLK_ENABLE();
  __HAL_RCC_GPIOF_CLK_ENABLE();
  __HAL_RCC_GPIOA_CLK_ENABLE();
  __HAL_RCC_GPIOB_CLK_ENABLE();

  /*Configure GPIO pin Output Level */
  HAL_GPIO_WritePin(GPIOB, M1_PWM_EN_U_Pin|M1_PWM_EN_V_Pin|M1_PWM_EN_W_Pin, GPIO_PIN_RESET);

  /*Configure GPIO pin : Start_Stop_Pin */
  GPIO_InitStruct.Pin = Start_Stop_Pin;
  GPIO_InitStruct.Mode = GPIO_MODE_IT_FALLING;
  GPIO_InitStruct.Pull = GPIO_NOPULL;
  HAL_GPIO_Init(Start_Stop_GPIO_Port, &GPIO_InitStruct);

  /*Configure GPIO pins : M1_PWM_EN_U_Pin M1_PWM_EN_V_Pin M1_PWM_EN_W_Pin */
  GPIO_InitStruct.Pin = M1_PWM_EN_U_Pin|M1_PWM_EN_V_Pin|M1_PWM_EN_W_Pin;
  GPIO_InitStruct.Mode = GPIO_MODE_OUTPUT_PP;
  GPIO_InitStruct.Pull = GPIO_PULLDOWN;
  GPIO_InitStruct.Speed = GPIO_SPEED_FREQ_HIGH;
  HAL_GPIO_Init(GPIOB, &GPIO_InitStruct);

}

void Error_Handler(void)
{
  __disable_irq();
  while (1)
  {
  }
}
